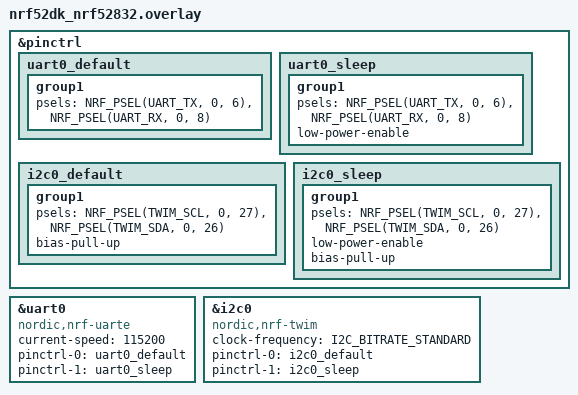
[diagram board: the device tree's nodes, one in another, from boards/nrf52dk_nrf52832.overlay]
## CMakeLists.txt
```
cmake_minimum_required(VERSION 3.20.0)

find_package(Zephyr REQUIRED HINTS $ENV{ZEPHYR_BASE})
project(garlic)

# Include directories for modular libs used by main
zephyr_include_directories(${CMAKE_CURRENT_LIST_DIR}/src)

# Source files organized by module
# For debugging bring-up, you can switch between apps here
add_subdirectory(src)
add_subdirectory(src/app)
 

# Embed current git hash into the firmware for RTT boot print
execute_process(
  COMMAND git rev-parse --short=12 HEAD
  WORKING_DIRECTORY ${CMAKE_CURRENT_LIST_DIR}
  OUTPUT_VARIABLE GARLIC_GIT_HASH
  OUTPUT_STRIP_TRAILING_WHITESPACE
  ERROR_QUIET
)
if (NOT GARLIC_GIT_HASH)
  set(GARLIC_GIT_HASH "unknown")
endif()
message(STATUS "Garlic git hash: ${GARLIC_GIT_HASH}")
target_compile_definitions(app PRIVATE GARLIC_GIT_HASH="${GARLIC_GIT_HASH}")

# Also make git hash visible to all zephyr_library() units
zephyr_compile_definitions(GARLIC_GIT_HASH="${GARLIC_GIT_HASH}")


# Also write the git hash to the build directory so integration tests can read it
file(WRITE ${CMAKE_BINARY_DIR}/garlic_git_hash.txt "${GARLIC_GIT_HASH}\n")
# Extra compiler warnings
zephyr_compile_options(-Wparentheses)

# -------------------------------
# Post-link guardrail: verify our app thread is linked
# -------------------------------
# This catches regressions where Zephyr's weak main() runs and our runtime
# thread is not present (e.g., due to link order or misplaced sources).
set(NM_FALLBACK nm)
if(DEFINED ENV{ZEPHYR_SDK_INSTALL_DIR})
  set(NM_CAND "$ENV{ZEPHYR_SDK_INSTALL_DIR}/arm-zephyr-eabi/bin/arm-zephyr-eabi-nm")
  if(EXISTS ${NM_CAND})
    set(NM_FALLBACK ${NM_CAND})
  endif()
endif()

add_custom_target(garlic_post_link ALL
  COMMAND ${CMAKE_COMMAND} -D ELF=${CMAKE_BINARY_DIR}/zephyr/zephyr.elf -D NM=${NM_FALLBACK} -P ${CMAKE_CURRENT_LIST_DIR}/cmake/check_symbol.cmake
  DEPENDS zephyr_final
  COMMENT "Post-link: verify runtime thread symbol present"
)

# -------------------------------
# clang-format targets (format / format-check)
# -------------------------------
find_program(CLANG_FORMAT_BIN NAMES clang-format clang-format-19 clang-format-18 clang-format-17)
if(CLANG_FORMAT_BIN)
  # Collect app source files for formatting
  file(GLOB_RECURSE APP_FORMAT_FILES
    RELATIVE ${CMAKE_CURRENT_LIST_DIR}
    src/*.c src/*.h src/*.cpp src/*.hpp
  )
  list(FILTER APP_FORMAT_FILES INCLUDE REGEX "^src/.*\\.(c|h|cpp|hpp)$")

  add_custom_target(format
    COMMAND ${CMAKE_COMMAND}
      -DCLANG_FORMAT_PROG=${CLANG_FORMAT_BIN}
      -DCWD=${CMAKE_CURRENT_LIST_DIR}
      -DFILES="${APP_FORMAT_FILES}"
      -DCHECK=0
      -P ${CMAKE_CURRENT_LIST_DIR}/cmake/run_clang_format.cmake
    WORKING_DIRECTORY ${CMAKE_CURRENT_LIST_DIR}
    COMMENT "Running clang-format (in-place) on app sources"
  )

  add_custom_target(format-check
    COMMAND ${CMAKE_COMMAND}
      -DCLANG_FORMAT_PROG=${CLANG_FORMAT_BIN}
      -DCWD=${CMAKE_CURRENT_LIST_DIR}
      -DFILES="${APP_FORMAT_FILES}"
      -DCHECK=1
      -P ${CMAKE_CURRENT_LIST_DIR}/cmake/run_clang_format.cmake
    WORKING_DIRECTORY ${CMAKE_CURRENT_LIST_DIR}
    COMMENT "Running clang-format --dry-run on app sources"
  )
else()
  message(STATUS "clang-format not found; format targets disabled")
endif()
```

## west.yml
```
manifest:
  remotes:
    - name: zephyrproject-rtos
      url-base: https://github.com/zephyrproject-rtos
  projects:
    - name: zephyr
      remote: zephyrproject-rtos
      revision: v3.7.0
      import:
        name-allowlist:
          - hal_nordic
          - cmsis
          - segger
  self:
    path: app
```

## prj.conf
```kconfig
# Enable serial
CONFIG_SERIAL=y
CONFIG_CONSOLE=y
CONFIG_UART_CONSOLE=n
CONFIG_UART_ASYNC_API=y

# Enable I2C with callback (async) support
CONFIG_I2C=y
CONFIG_I2C_CALLBACK=y

# Enable GPIO for LED control
CONFIG_GPIO=y

# Use async DMA, not IRQ/polling
CONFIG_UART_INTERRUPT_DRIVEN=n

# Enable both UART and RTT for debugging
CONFIG_USE_SEGGER_RTT=y
CONFIG_RTT_CONSOLE=n

# Thread and kernel features
CONFIG_MAIN_STACK_SIZE=2048
CONFIG_HEAP_MEM_POOL_SIZE=8192

# Enable logging (but keep it minimal for production)
CONFIG_LOG=y
CONFIG_LOG_DEFAULT_LEVEL=3
CONFIG_LOG_BACKEND_UART=n
CONFIG_LOG_BACKEND_RTT=y
CONFIG_UART_USE_RUNTIME_CONFIGURE=y

# Ensure RTT logs appear reliably during early boot/reset
CONFIG_PRINTK=y
CONFIG_LOG_MODE_IMMEDIATE=n
# Increase RTT buffer to avoid early overflow (non-blocking)
CONFIG_SEGGER_RTT_BUFFER_SIZE_UP=1024
CONFIG_LOG_BACKEND_RTT_OUTPUT_BUFFER_SIZE=1024
# Avoid blocking the app if RTT host is not attached yet
CONFIG_LOG_BACKEND_RTT_MODE_BLOCK=n

# Make printk over RTT block briefly until host attaches (prevents dropping boot lines)
# ~2s total retry window for early printk
CONFIG_RTT_TX_RETRY_CNT=2000
CONFIG_RTT_TX_RETRY_DELAY_MS=1
#CONFIG_RTT_TX_RETRY_IN_INTERRUPT=y  # optional; keep off to avoid ISR stalls

# Treat warnings as errors for medical-grade quality
CONFIG_COMPILER_WARNINGS_AS_ERRORS=y
CONFIG_REBOOT=y
CONFIG_FLASH=y

# Bluetooth (NUS) peripheral to expose command transport over BLE
CONFIG_BT=y
CONFIG_BT_PERIPHERAL=y
CONFIG_BT_GAP_AUTO_UPDATE_CONN_PARAMS=n
CONFIG_BT_AUTO_PHY_UPDATE=n
CONFIG_BT_AUTO_DATA_LEN_UPDATE=n
CONFIG_BT_DEVICE_NAME="GarlicDK"
CONFIG_BT_MAX_CONN=1
CONFIG_BT_MAX_PAIRED=1
CONFIG_BT_GATT_SERVICE_CHANGED=y
CONFIG_BT_ZEPHYR_NUS=y
CONFIG_BT_ZEPHYR_NUS_DEFAULT_INSTANCE=y
CONFIG_BT_DIS=y
CONFIG_BT_GATT_CACHING=n

# Increase BT buffers slightly for stability during discovery
CONFIG_BT_BUF_ACL_RX_COUNT=10
CONFIG_BT_BUF_ACL_TX_COUNT=10
```

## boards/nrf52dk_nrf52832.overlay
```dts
/*
 * Device tree overlay for nRF52-DK UART configuration with FTDI
 * Using default UART pins P0.06 (TX) and P0.08 (RX)
 */

&pinctrl {
    uart0_default: uart0_default {
        group1 {
            /* TX on P0.06, RX on P0.08 - FTDI wiring */
            psels = <NRF_PSEL(UART_TX, 0, 6)>,
                    <NRF_PSEL(UART_RX, 0, 8)>;
        };
    };

    uart0_sleep: uart0_sleep {
        group1 {
            psels = <NRF_PSEL(UART_TX, 0, 6)>,
                    <NRF_PSEL(UART_RX, 0, 8)>;
            low-power-enable;
        };
    };
};

&uart0 {
    status = "okay";
    compatible = "nordic,nrf-uarte";
    current-speed = <115200>;
    
    /* Use our custom pinctrl for FTDI connection */
    pinctrl-0 = <&uart0_default>;
    pinctrl-1 = <&uart0_sleep>;
    pinctrl-names = "default", "sleep";
    
    /* Enable hardware flow control if needed */
    /* hw-flow-control; */
};

/* Enable I2C0 on P0.27 (SCL) and P0.26 (SDA) at 400 kHz */
&pinctrl {
    i2c0_default: i2c0_default {
        group1 {
            psels = <NRF_PSEL(TWIM_SCL, 0, 27)>,
                    <NRF_PSEL(TWIM_SDA, 0, 26)>;
            /* Enable weak internal pull-ups as a fallback when no external resistors are present.
             * Note: For robust I2C, external 2.2k–10k pull-ups are recommended (TMP119 datasheet).
             */
            bias-pull-up;
        };
    };

    i2c0_sleep: i2c0_sleep {
        group1 {
            psels = <NRF_PSEL(TWIM_SCL, 0, 27)>,
                    <NRF_PSEL(TWIM_SDA, 0, 26)>;
            low-power-enable;
            /* Keep pull-ups enabled in sleep to avoid floating lines if needed */
            bias-pull-up;
        };
    };
};

&i2c0 {
    compatible = "nordic,nrf-twim";
    status = "okay";
    clock-frequency = <I2C_BITRATE_STANDARD>;
    pinctrl-0 = <&i2c0_default>;
    pinctrl-1 = <&i2c0_sleep>;
    pinctrl-names = "default", "sleep";
};
```

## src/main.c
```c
#include <zephyr/kernel.h>
#include <zephyr/sys/printk.h>
#include <zephyr/drivers/gpio.h>

/* The nRF52-DK has 4 LEDs, we'll use LED1 (green) */
#define LED0_NODE DT_ALIAS(led0)
static const struct gpio_dt_spec led = GPIO_DT_SPEC_GET(LED0_NODE, gpios);

int main(void)
{
    int ret;
    bool led_state = true;
    
    printk("LED Blinky at 3Hz on nRF52-DK!\n");
    
    /* Configure LED */
    if (!gpio_is_ready_dt(&led)) {
        printk("Error: LED device not ready\n");
        return -1;
    }
    
    ret = gpio_pin_configure_dt(&led, GPIO_OUTPUT_ACTIVE);
    if (ret < 0) {
        printk("Error: Failed to configure LED pin\n");
        return -1;
    }
    
    printk("Blinking LED at 3Hz (3 times per second)...\n");
    
    while (1) {
        /* Toggle LED */
        gpio_pin_set_dt(&led, led_state);
        led_state = !led_state;
        
        /* 3Hz = 3 cycles per second
         * Period = 1000ms / 3 = 333ms
         * Half period (on/off time) = 166ms */
        k_msleep(166);
    }
    
    return 0;
}
```

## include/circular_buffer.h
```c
/**
 * @file circular_buffer.h
 * @brief Lock-free circular buffer implementation for UART DMA
 *
 * This circular buffer is designed to work with DMA transfers,
 * providing non-blocking write operations and efficient memory usage.
 */

#ifndef CIRCULAR_BUFFER_H
#define CIRCULAR_BUFFER_H

#include <stdbool.h>
#include <stddef.h>
#include <stdint.h>

#ifdef __cplusplus
extern "C" {
#endif

/**
 * @brief Circular buffer structure
 */
typedef struct {
    uint8_t *buffer;      /**< Pointer to data buffer */
    size_t size;          /**< Total size of buffer */
    volatile size_t head; /**< Write position (producer) */
    volatile size_t tail; /**< Read position (consumer) */
} circular_buffer_t;

/**
 * @brief Initialize a circular buffer
 *
 * @param cb Pointer to circular buffer structure
 * @param buffer Pointer to data storage
 * @param size Size of data storage in bytes
 * @return 0 on success, -1 on error
 */
int circular_buffer_init(circular_buffer_t *cb, uint8_t *buffer, size_t size);

/**
 * @brief Reset buffer to empty state
 *
 * @param cb Pointer to circular buffer
 */
void circular_buffer_reset(circular_buffer_t *cb);

/**
 * @brief Write data to buffer (non-blocking)
 *
 * @param cb Pointer to circular buffer
 * @param data Pointer to data to write
 * @param len Length of data to write
 * @return Number of bytes actually written
 */
size_t circular_buffer_write(circular_buffer_t *cb, const uint8_t *data, size_t len);

/**
 * @brief Read data from buffer
 *
 * @param cb Pointer to circular buffer
 * @param data Pointer to destination buffer
 * @param len Maximum length to read
 * @return Number of bytes actually read
 */
size_t circular_buffer_read(circular_buffer_t *cb, uint8_t *data, size_t len);

/**
 * @brief Peek at data without removing it
 *
 * @param cb Pointer to circular buffer
 * @param data Pointer to destination buffer
 * @param len Maximum length to peek
 * @return Number of bytes actually peeked
 */
size_t circular_buffer_peek(const circular_buffer_t *cb, uint8_t *data, size_t len);

/**
 * @brief Get number of bytes available to read
 *
 * @param cb Pointer to circular buffer
 * @return Number of bytes available
 */
size_t circular_buffer_available(const circular_buffer_t *cb);

/**
 * @brief Get free space available for writing
 *
 * @param cb Pointer to circular buffer
 * @return Number of bytes free
 */
size_t circular_buffer_free_space(const circular_buffer_t *cb);

/**
 * @brief Check if buffer is empty
 *
 * @param cb Pointer to circular buffer
 * @return true if empty, false otherwise
 */
bool circular_buffer_is_empty(const circular_buffer_t *cb);

/**
 * @brief Check if buffer is full
 *
 * @param cb Pointer to circular buffer
 * @return true if full, false otherwise
 */
bool circular_buffer_is_full(const circular_buffer_t *cb);

/**
 * @brief Get linear read buffer for DMA operations
 *
 * Gets a pointer and length for a continuous block that can be read.
 * This is useful for DMA operations that need contiguous memory.
 *
 * @param cb Pointer to circular buffer
 * @param data_ptr Output: pointer to start of readable data
 * @param len Output: length of continuous readable data
 * @return 0 on success, -1 if buffer is empty
 */
int circular_buffer_get_read_block(const circular_buffer_t *cb, uint8_t **data_ptr, size_t *len);

/**
 * @brief Advance read pointer after DMA read
 *
 * @param cb Pointer to circular buffer
 * @param len Number of bytes that were read by DMA
 */
void circular_buffer_advance_read(circular_buffer_t *cb, size_t len);

/**
 * @brief Get linear write buffer for DMA operations
 *
 * Gets a pointer and length for a continuous block that can be written.
 *
 * @param cb Pointer to circular buffer
 * @param data_ptr Output: pointer to start of writable area
 * @param len Output: length of continuous writable area
 * @return 0 on success, -1 if buffer is full
 */
int circular_buffer_get_write_block(circular_buffer_t *cb, uint8_t **data_ptr, size_t *len);

/**
 * @brief Advance write pointer after DMA write
 *
 * @param cb Pointer to circular buffer
 * @param len Number of bytes that were written by DMA
 */
void circular_buffer_advance_write(circular_buffer_t *cb, size_t len);

#ifdef __cplusplus
}
#endif

#endif /* CIRCULAR_BUFFER_H */
```
